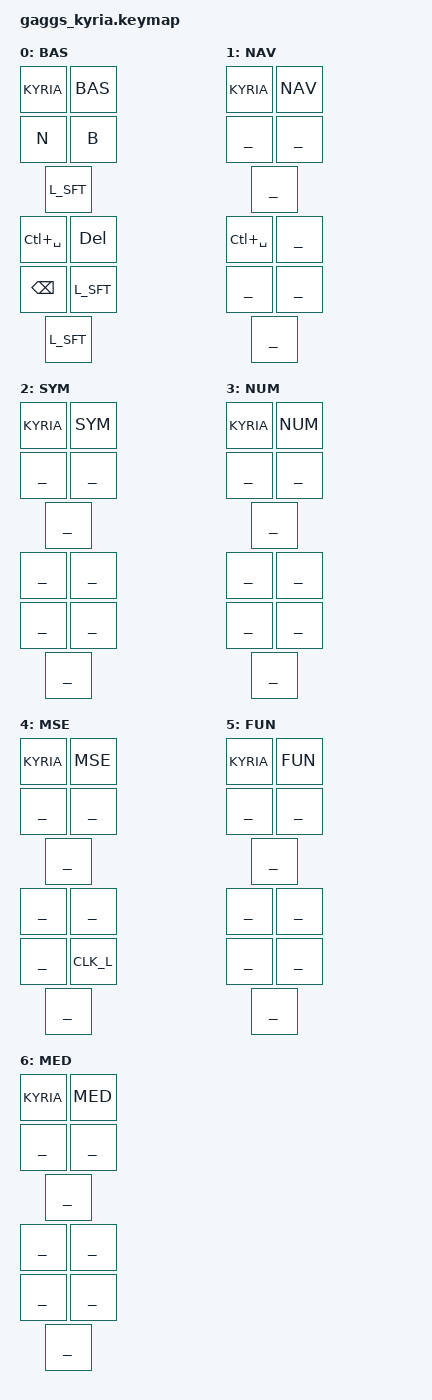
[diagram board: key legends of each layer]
/*
 * Kyria. 공통 42키는 config/keymap_common.dtsi 에서 고친다.
 * 여기는 Kyria에만 있는 키(아래 줄 안쪽 2개, 엄지 6개)만 적는다.
 *
 *   공통        [ 6 ][ 6 ]
 *   공통        [ 6 ][ 6 ]
 *   공통        [ 6 ] 안쪽 2 [ 6 ]
 *   왼엄지밖 1 [ 공통 3 ] 왼엄지안 2 | 오른엄지안 2 [ 공통 3 ] 오른엄지밖 1
 */

#include <dt-bindings/zmk/pointing.h>

#define LEFT_KEYS    0 1 2 3 4 5  12 13 14 15 16 17  24 25 26 27 28 29 30  38 39 40 41 42 43
#define RIGHT_KEYS   6 7 8 9 10 11  18 19 20 21 22 23  31 32 33 34 35 36 37  44 45 46 47 48 49
#define LEFT_THUMBS  38 39 40 41 42 43
#define RIGHT_THUMBS 44 45 46 47 48 49

#include "keymap_common.dtsi"

#define KYRIA(...) KYRIA_(__VA_ARGS__)
#define KYRIA_(l0, r0, l1, r1, l2, r2, lt, rt, inner, tlo, tli, tri, tro) \
    l0 r0  l1 r1  l2 inner r2  tlo lt tli tri rt tro

/ {
    keymap {
        compatible = "zmk,keymap";

        default_layer {
            display-name = "BAS";
            bindings = <KYRIA(BAS,
                /* 안쪽       */ &kp N  &kp B,
                /* 왼엄지밖   */ L_SFT,
                /* 왼엄지안   */ &kp LC(SPACE)  &kp DEL,
                /* 오른엄지안 */ &kp BSPC  L_SFT,
                /* 오른엄지밖 */ L_SFT
            )>;
        };

        nav_layer {
            display-name = "NAV";
            bindings = <KYRIA(NAV,
                /* 안쪽       */ ___  ___,
                /* 왼엄지밖   */ ___,
                /* 왼엄지안   */ &kp LC(SPACE)  ___,
                /* 오른엄지안 */ ___  ___,
                /* 오른엄지밖 */ ___
            )>;
        };

        symbol_layer {
            display-name = "SYM";
            bindings = <KYRIA(SYM,
                /* 안쪽       */ ___  ___,
                /* 왼엄지밖   */ ___,
                /* 왼엄지안   */ ___  ___,
                /* 오른엄지안 */ ___  ___,
                /* 오른엄지밖 */ ___
            )>;
        };

        number_layer {
            display-name = "NUM";
            bindings = <KYRIA(NUM,
                /* 안쪽       */ ___  ___,
                /* 왼엄지밖   */ ___,
                /* 왼엄지안   */ ___  ___,
                /* 오른엄지안 */ ___  ___,
                /* 오른엄지밖 */ ___
            )>;
        };

        mouse_layer {
            display-name = "MSE";
            bindings = <KYRIA(MSE,
                /* 안쪽       */ ___  ___,
                /* 왼엄지밖   */ ___,
                /* 왼엄지안   */ ___  ___,
                /* 오른엄지안 */ ___  CLK_L,
                /* 오른엄지밖 */ ___
            )>;
        };

        func_layer {
            display-name = "FUN";
            bindings = <KYRIA(FUN,
                /* 안쪽       */ ___  ___,
                /* 왼엄지밖   */ ___,
                /* 왼엄지안   */ ___  ___,
                /* 오른엄지안 */ ___  ___,
                /* 오른엄지밖 */ ___
            )>;
        };

        media_layer {
            display-name = "MED";
            bindings = <KYRIA(MED,
                /* 안쪽       */ ___  ___,
                /* 왼엄지밖   */ ___,
                /* 왼엄지안   */ ___  ___,
                /* 오른엄지안 */ ___  ___,
                /* 오른엄지밖 */ ___
            )>;
        };

    };
};
